AUTOSAR XML (schema 00046)
package /Runnable_lab
  sender receiver interface SRI_Throttle
    data CMD_Throttle: type=uint32
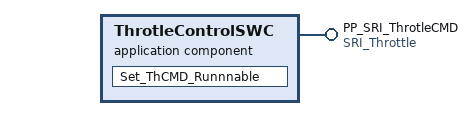
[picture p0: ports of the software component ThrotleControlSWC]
  application sw component type ThrotleControlSWC
    provide port PP_SRI_ThrotleCMD: provided-interface=SRI_Throttle
    behavior ThControl_Behaviuor
      runnable Set_ThCMD_Runnnable: symbol=Set_ThCMD
